# R7FS3A17 register map
Vendor: Renesas; Series: S3; File version: 1.2
CPU: CM4 r0p1, little endian, MPU, FPU, VTOR, 4 interrupt priority bits
Registers are 8-bit, read-write, reset 0x0 unless marked. A register's access mark holds for its fields unless they carry their own. Offsets are from the block's base; [hi:lo] are bit positions; <NAME> marks a mode.

## SDHI0 — SD Host Interface 0
Base 0x40062000
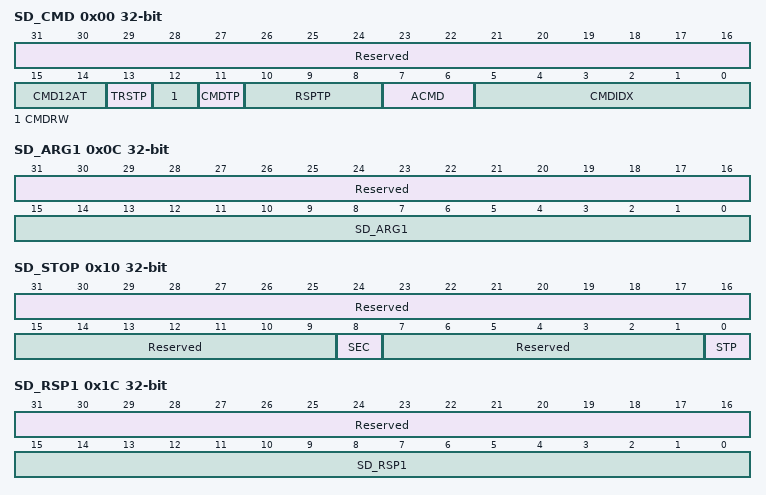
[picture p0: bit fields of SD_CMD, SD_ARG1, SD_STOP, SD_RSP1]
0x00 SD_CMD 32-bit — Command Type Register
  [31:16] Reserved — These bits are read as 0000000000000000. The write value should be 0000000000000000.
  [15:14] CMD12AT — CMD12 Automatic Issue Select
    0=CMD12 is automatically issued at multi-block transfer; 1=CMD12 is not automatically issued at multi-block transfer; other=others (Setting prohibited)
  [13] TRSTP — Block Transfer Select
    0=Single block transfer; 1=Multiple blocks transfer
  [12] CMDRW — Data Transfer Direction Select
    0=Write (SD/MMC host interface -> SD card/MMC); 1=Read (SD/MMC host interface <- SD card/MMC)
  [11] CMDTP — Data Transfer Select
    0=Command does not include data transfer (bc, bcr, or ac); 1=Command includes data transfer (adtc)
  [10:8] RSPTP — Response Type Select NOTE:Some commands cannot be used in Normal Mode. Refer to Table 37.3 and set the RSPTP[2:0] bits.
    0=Normal mode The response type and the transfer mode are selected by SD_CMD[7:0], and the SD_CMD[15:11] setting is disabled; 3=Expansion mode and no response; 4=Expansion mode and R1, R5, R6, or R7 response; 5=Expansion mode and R1b response; 6=Expansion mode and R2 response; 7=Expansion mode and R3 or R4 response; other=others (Settings prohibited.)
  [7:6] ACMD — Command Type Select
    0=CMD; 1=ACMD; other=others (Setting prohibited)
  [5:0] CMDIDX — Command Index Field Value Select These bits specify Command Format[45:40] (command index). [Examples] CMD6: SD_CMD[7:0] = 8'b00_000110 CMD18: SD_CMD[7:0] = 8'b00_010010 ACMD13: SD_CMD[7:0] = 8'b01_001101
0x08 SD_ARG 32-bit — SD Command Argument Register
  [31:0] SD_ARG — Argument Register Set command format[39:8] (argument)
0x0C SD_ARG1 32-bit — SD Command Argument Register 1
  [31:16] Reserved — These bits are read as 0000000000000000. The write value should be 0000000000000000.
  [15:0] SD_ARG1 — Argument Register 1 Set command format[39:24] (argument)
0x10 SD_STOP 32-bit — Data Stop Register
  [31:16] Reserved — These bits are read as 0000000000000000. The write value should be 0000000000000000.
  [15:9] Reserved — These bits are read as 0000000. The write value should be 0000000.
  [8] SEC — Block Count Register Value Select Set SEC to 1 at multiple block transfer. When SD_CMD is set as follows to start the command sequence while SEC is set to 1, CMD12 is automatically issued to stop multi-block transfer with the number of blocks which is set to SD_SECCNT. 1. CMD18 or CMD25 in normal mode (SD_CMD[10:8] = 000) 2. SD_CMD[15:13] = 001 in extended mode (CMD12 is automatically issued, multiple block transfer) When the command sequence is halted because of a communications error or timeout, CMD12 is not automatically issued. NOTE: Do not change the value of this bit when the CBSY bit in SD_INFO2 is set to 1.
    0=SD_SECCNT register value is invalid; 1=SD_SECCNT register value is valid
  [7:1] Reserved — These bits are read as 0000000. The write value should be 0000000.
  [0] STP — Transfer Stop Data transfer stops when this bit is set to 1
0x14 SD_SECCNT 32-bit — Block Count Register
  [31:0] SD_SECCNT — Number of Transfer Blocks NOTE: Do not change the value of this bit when the CBSY bit in SD_INFO2 is set to 1.
0x18 SD_RSP10 32-bit ro — SD Card Response Register 10
  [31:0] SD_RSP10 — Store the response from the SD card/MMC
0x1C SD_RSP1 32-bit ro — SD Card Response Register 1
  [31:16] Reserved — These bits are read as 0000000000000000.
  [15:0] SD_RSP1 — Store the response from the SD card/MMC
0x20 SD_RSP32 32-bit ro — SD Card Response Register 32
  [31:0] SD_RSP32 — Store the response from the SD card/MMC
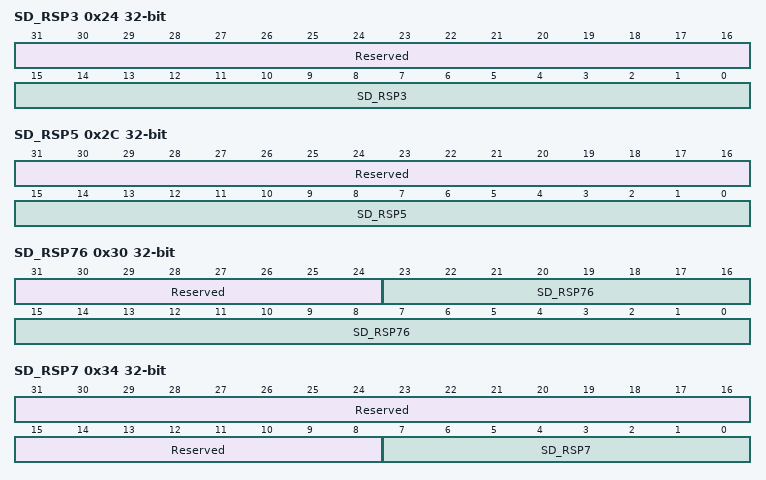
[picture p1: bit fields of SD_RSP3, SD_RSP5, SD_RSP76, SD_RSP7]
0x24 SD_RSP3 32-bit ro — SD Card Response Register 3
  [31:16] Reserved — These bits are read as 0000000000000000.
  [15:0] SD_RSP3 — Store the response from the SD card/MMC
0x28 SD_RSP54 32-bit ro — SD Card Response Register 54
  [31:0] SD_RSP54 — Store the response from the SD card/MMC
0x2C SD_RSP5 32-bit ro — SD Card Response Register 5
  [31:16] Reserved — These bits are read as 0000000000000000.
  [15:0] SD_RSP5 — Store the response from the SD card/MMC
0x30 SD_RSP76 32-bit ro — SD Card Response Register 76
  [31:24] Reserved — These bits are read as 00000000.
  [23:0] SD_RSP76 — Store the response from the SD card/MMC
0x34 SD_RSP7 32-bit ro — SD Card Response Register 7
  [31:8] Reserved — These bits are read as 000000000000000000000000.
  [7:0] SD_RSP7 — Store the response from the SD card/MMC
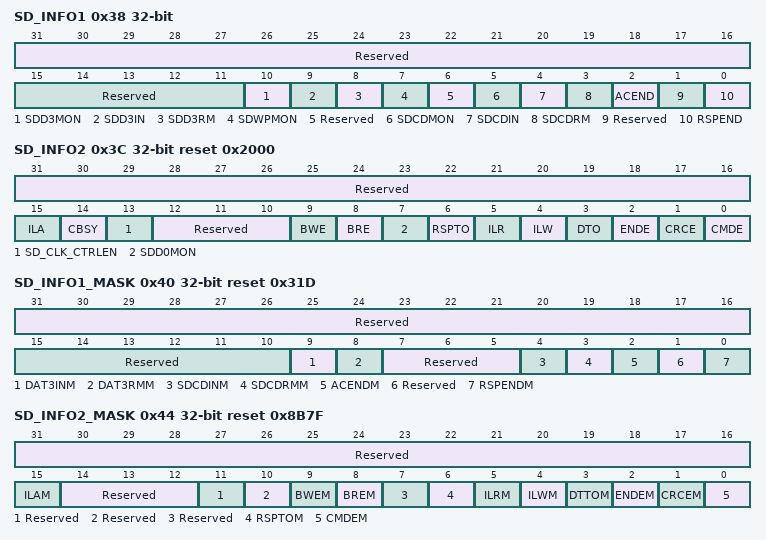
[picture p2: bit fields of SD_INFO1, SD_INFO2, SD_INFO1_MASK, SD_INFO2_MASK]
0x38 SD_INFO1 32-bit (reset mask 0xFFFFFB5F) — SD Card Interrupt Flag Register 1
  [31:16] Reserved — These bits are read as 0000000000000000. The write value should be 0000000000000000.
  [15:11] Reserved — These bits are read as 00000. The write value should be 00000.
  [10] SDD3MON ro — Inticates the SDnDAT3 State Flag
    0=SDnDAT3 is set to 0; 1=SDnDAT3 is set to 1
  [9] SDD3IN write-0-clears read-modifies — SDnDAT3 Card Insertion Flag
    0=SD card insertion is not detected; 1=SD card insertion is detected
  [8] SDD3RM write-0-clears read-modifies — SD0DAT3 Card Removal Flag
    0=SD card removal is not detected; 1=SD card removal is detected
  [7] SDWPMON ro — SD0WP Pin Monitor Detection Flag
    0=SDnWP is set to 1; 1=SDnWP is set to 0
  [6] Reserved — This bit is read as 0. The write value should be 0.
  [5] SDCDMON ro — SD0CD Pin Monitor Detection Flag
    0=SD0WP pin level is high; 1=SD0WP pin level is low
  [4] SDCDIN write-0-clears read-modifies — SD0CD Insertion Detection Flag
    0=SD card/MMC insertion is not detected by the SD0CD pin; 1=SD card/MMC insertion is detected by the SD0CD pin
  [3] SDCDRM write-0-clears read-modifies — SD0CD Removal Detection Flag
    0=SD card/MMC removal is not detected by the SD0CD pin; 1=SD card/MMC removal is detected by the SD0CD pin
  [2] ACEND write-0-clears read-modifies — Access End Detection Flag
    0=Access end is not detected; 1=Access end is detected
  [1] Reserved — This bit is read as 0. The write value should be 0.
  [0] RSPEND — Response End Detection Flag
    0=Response end is not detected; 1=Response end is detected
0x3C SD_INFO2 32-bit reset 0x2000 (reset mask 0xFFFFFF7F) — SD Card Interrupt Flag Register 2
  [31:16] Reserved — These bits are read as 0000000000000000. The write value should be 0000000000000000.
  [15] ILA write-0-clears read-modifies — Illegal Access Error
    0=Illegal access error is not detected; 1=Illegal access error is detected
  [14] CBSY ro — Command Type Register Busy
    0=A command sequence is being executed; 1=A command sequence has been completed
  [13] SD_CLK_CTRLEN ro — When a command sequence is started by writing to SD_CMD, the CBSY bit is set to 1 and, at the same time, the SCLKDIVEN bit is set to 0. The SCLKDIVEN bit is set to 1 after 8 cycles of SDCLK have elapsed after setting of the CBSY bit to 0 due to completion of the command sequence.
    0=The SD/MMC bus (CMD, DAT) is busy. Writing to the SCLKEN and DIV bits in SD_CLK_CTRL is not possible.; 1=The SD/MMC bus (CMD, DAT) is not busy
  [12:10] Reserved — These bits are read as 000. The write value should be 000.
  [9] BWE write-0-clears read-modifies — SD_BUF Write Enable
    1=Data can be written in SD_BUF0; 0=Data cannot be written in SD_BUF0
  [8] BRE write-0-clears read-modifies — SD_BUF Read Enable
    1=Data can be read from SD_BUF0; 0=Data cannot be read from SD_BUF0
  [7] SDD0MON ro — SDDAT0 Indicates the SDDAT0 state of the port specified by SD_PORTSEL.
    1=SDDAT0 is set to 1; 0=SDDAT0 is set to 0
  [6] RSPTO write-0-clears read-modifies — Response Timeout
    0=Response timeout is not detected; 1=Response timeout is detected
  [5] ILR write-0-clears read-modifies — SD_BUF Illegal Read Access
    0=Illegal read access to the SD_BUF register is not detected; 1=Illegal read access to the SD_BUF register is detected
  [4] ILW write-0-clears read-modifies — SD_BUF Illegal Write Access
    0=Illegal write access to the SD_BUF register is not detected; 1=Illegal write access to the SD_BUF register is detected
  [3] DTO write-0-clears read-modifies — Data Timeout
    0=Data timeout not is detected; 1=Data timeout is detected
  [2] ENDE write-0-clears read-modifies — END Error
    0=End bit error is not detected; 1=End bit error is detected
  [1] CRCE write-0-clears read-modifies — CRC Error
    0=CRC error is not detected; 1=CRC error is detected
  [0] CMDE write-0-clears read-modifies — Command Error
    0=Command error is not detected; 1=Command error is detected
0x40 SD_INFO1_MASK 32-bit reset 0x31D — SD_INFO1 Interrupt Mask Register
  [31:16] Reserved — These bits are read as 0000000000000000. The write value should be 0000000000000000.
  [15:10] Reserved — These bits are read as 000000. The write value should be 000000.
  [9] DAT3INM — SDnDAT3 Card Insertion Interrupt Request Mask
    0=SD card insertion interrupt request by the SDnDAT3 is not masked; 1=SD card insertion interrupt request by the SDnDAT3 is masked
  [8] DAT3RMM — SDnDAT3 Card Removal Interrupt Request Mask
    0=SD card removal interrupt request by the SDnDAT3 is not masked; 1=SD card removal interrupt request by the SDnDAT3 is masked
  [7:5] Reserved — These bits are read as 000. The write value should be 000.
  [4] SDCDINM — SD0CD Insertion Interrupt Request Mask
    0=SD card/MMC insertion interrupt request by the SD0CD pin is not masked; 1=SD card/MMC insertion interrupt request by the SD0CD pin is masked
  [3] SDCDRMM — SD0CD Removal Interrupt Request Mask
    0=SD card/MMC removal interrupt request by the SD0CD pin is not masked; 1=SD card/MMC removal interrupt request by the SD0CD pin is masked
  [2] ACENDM — Access End Interrupt Request Mask
    0=Access end interrupt request is not masked; 1=Access end interrupt request is masked
  [1] Reserved — This bit is read as 0. The write value should be 0.
  [0] RSPENDM — Response End Interrupt Request Mask
    0=Response end interrupt request is not masked; 1=Response end interrupt request is masked
0x44 SD_INFO2_MASK 32-bit reset 0x8B7F — SD_INFO2 Interrupt Mask Register
  [31:16] Reserved — These bits are read as 0000000000000000. The write value should be 0000000000000000.
  [15] ILAM — Illegal Access Error Interrupt Request Mask
    0=Illegal access error interrupt request is not masked; 1=Illegal access error interrupt request is masked
  [14:12] Reserved — These bits are read as 000. The write value should be 000.
  [11] Reserved — This bit is read as 1. The write value should be 1.
  [10] Reserved — This bit is read as 0. The write value should be 0.
  [9] BWEM — BWE Interrupt Request Mask
    0=Write enable interrupt request for the SD_BUF register is not masked; 1=Write enable interrupt request for the SD_BUF register is masked
  [8] BREM — BRE Interrupt Request Mask
    0=Read enable interrupt request for the SD buffer not masked; 1=Read enable interrupt request for the SD buffer masked
  [7] Reserved — This bit is read as 0. The write value should be 0.
  [6] RSPTOM — Response Timeout Interrupt Request Mask
    0=Response timeout interrupt request is not masked; 1=Response timeout interrupt request is masked
  [5] ILRM — SD_BUF Register Illegal Read Interrupt Request Mask
    0=Illegal read detection interrupt request for the SD_BUF register is not masked; 1=Illegal read detection interrupt request for the SD_BUF register is masked
  [4] ILWM — SD_BUF Register Illegal Write Interrupt Request Mask
    0=Illegal write detection interrupt request for the SD_BUF register is not masked; 1=Illegal write detection interrupt request for the SD_BUF register is masked
  [3] DTTOM — Data Timeout Interrupt Request Mask
    0=Data timeout interrupt request is not masked; 1=Data timeout interrupt request is masked
  [2] ENDEM — End Bit Error Interrupt Request Mask
    0=End bit detection error interrupt request is not masked; 1=End bit detection error interrupt request is masked
  [1] CRCEM — CRC Error Interrupt Request Mask
    0=CRC error interrupt request is not masked; 1=CRC error interrupt request is masked
  [0] CMDEM — Command Error Interrupt Request Mask
    0=Command error interrupt request is not masked; 1=Command error interrupt request is masked
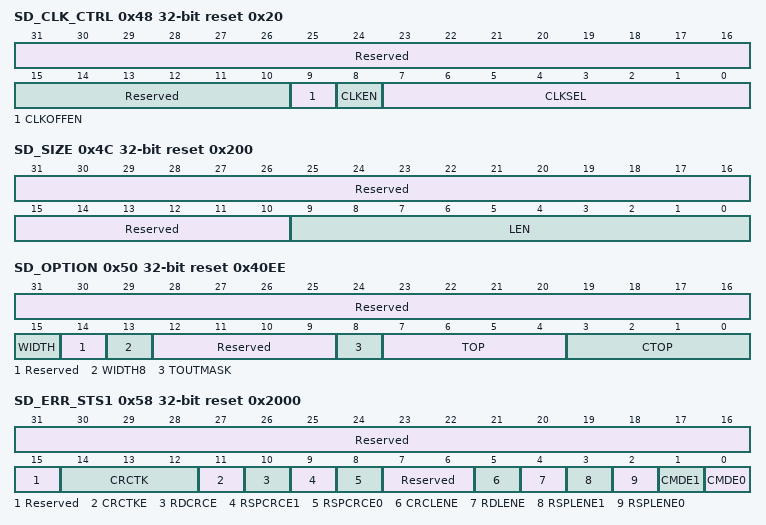
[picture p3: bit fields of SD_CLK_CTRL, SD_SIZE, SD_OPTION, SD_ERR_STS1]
0x48 SD_CLK_CTRL 32-bit reset 0x20 — SD Clock Control Register
  [31:16] Reserved — These bits are read as 0000000000000000. The write value should be 0000000000000000.
  [15:10] Reserved — These bits are read as 000000. The write value should be 000000.
  [9] CLKOFFEN — SD/MMC Clock Output Automatic Control Enable
    0=Automatic control for SD/MMC Clock output is disabled; 1=Automatic control for SD/MMC Clock output is enabled
  [8] CLKEN — SD/MMC Clock Output Control Enable
    0=SD/MMC Clock output is disabled. The SDCLK signal is fixed 0.; 1=SD/MMC Clock output is enabled
  [7:0] CLKSEL — SDHI Clock Frequency Select
    0=PCLKA divided by 2; 1=PCLKA divided by 4; 2=PCLKA divided by 8; 4=PCLKA divided by 16; 8=PCLKA divided by 32; 16=PCLKA divided by 64; 32=PCLKA divided by 128; 64=PCLKA divided by 256; 128=PCLKA divided by 512; other=others (Settings prohibited.)
0x4C SD_SIZE 32-bit reset 0x200 — Transfer Data Length Register
  [31:10] Reserved — These bits are read as 0000000000000000000000. The write value should be 0000000000000000000000.
  [9:0] LEN — Transfer Data Size These bits specify a size between 1 and 512 bytes for the transfer of single blocks. In cases of multiple block transfer with automatic issuing of CMD12 (CMD18 and CMD25), the only specifiable transfer data size is 512 bytes. Furthermore, in cases of multiple block transfer without automatic issuing of CMD12, as well as 512 bytes, 32, 64, 128, and 256 bytes are specifiable. However, in the reading of 32, 64, 128, and 256 bytes for the transfer of multiple blocks, this is restricted to multiple block transfer by CMD53.Additionally, if a command accompanies data transfer, do not set these bits to 0.
0x50 SD_OPTION 32-bit reset 0x40EE — SD Card Access Control Option Register
  [31:16] Reserved — These bits are read as 0000000000000000. The write value should be 0000000000000000.
  [15] WIDTH — Bus Width NOTE: The initial value is applied at a reset and when the SOFT_RST.SDRST flag is 0.
    0=4-bit width (WIDTH8=0) / 8-bit width (WIDTH8=1); 1=1-bit width (WIDTH8=0 or 1 )
  [14] Reserved — This bit is read as 1. The write value should be 1.
  [13] WIDTH8 — Bus Width see b15, WIDTH bit
  [12:9] Reserved — These bits are read as 0000. The write value should be 0000.
  [8] TOUTMASK — Timeout MASK When timeout occurs in case of inactivating timeout, software reset should be executed to terminate command sequence.
    0=Activate Timeout; 1=Inactivate Timeout(RSPTO bit and DTO bit of SD_INFO2 and SD_ERR_STS2 won't be set)
  [7:4] TOP — Timeout Counter
    15=Setting prohibited; other=others (SDHI clock x 2^(TOP+13))
  [3:0] CTOP — Card Detection Time Counter
    15=Setting prohibited; other=others (PCLKA x 2^(TOP+10))
0x58 SD_ERR_STS1 32-bit ro reset 0x2000 — SD Error Status Register 1
  [31:15] Reserved — These bits are read as 00000000000000000.
  [14:12] CRCTK — CRC Status Token Store the CRC status token value (normal value is 010b)
  [11] CRCTKE — CRC Status Token Error Flag
    0=Error detected in CRC status token; 1=No error detected in CRC status token
  [10] RDCRCE — Read Data CRC Error Flag
    0=CRC error detected in read data; 1=No CRC error detected in read data
  [9] RSPCRCE1 — Response CRC Error Flag 1 NOTE: In cases where CMD12 is issued by setting a command index in SD_CMD, this is indicated in RSPCRCE0.
    0=CRC error detected in command response; 1=No CRC error detected in command response (by setting the SD_CMD.CMDIDX[5:0] bits, the error that occurs by issuing CMD12 is indicated by the RSPCRCE0 flag)
  [8] RSPCRCE0 — Response CRC Error Flag 0 NOTE: other than a response to a command issued within a command sequence
    0=CRC error detected in command response; 1=No CRC error detected in command response
  [7:6] Reserved — These bits are read as 00.
  [5] CRCLENE — CRC Status Token Length Error Flag
    0=CRC status token length error did not occur; 1=CRC status token length error occurred
  [4] RDLENE — Read Data Length Error Flag
    0=Read data length error did not occur; 1=Read data length error occurred
  [3] RSPLENE1 — Response Length Error Flag 1 NOTE: In cases where CMD12 is issued by setting a command index in SD_CMD, this is indicated in RSPLENE0.
    0=Command response length is error free; 1=Command response length is in error (by setting the SD_CMD.CMDIDX[5:0] bits, the error that occurs by issuing CMD12 is indicated by the RSPLENE0 flag)
  [2] RSPLENE0 — Response Length Error Flag 0 NOTE: other than a response to a command issued within a command sequence
    0=Command1 response length is error free; 1=Command1 response length is in error
  [1] CMDE1 — Command Error Flag 1 NOTE: In cases where CMD12 is issued by setting a command index in SD_CMD, this is Indicated in CMDE0.
    0=After a command*2 was issued, a response was received in less than 640 cycles of the SD/MMC clock; 1=After a command*2 was issued, a response was not received even after 640 cycles or more of the SD/MMC clock elapsed (by setting the SD_CMD.CMDIDX[5:0] bits, the error that occurs by issuing CMD12 is indicated by the RSPTO0 flag)
  [0] CMDE0 — Command Error Flag 0 NOTE: other than a response to a command issued within a command sequence
    0=After a command*1 was issued, a response was received in less than 640 cycles of the SD/MMC clock; 1=After a command*1 was issued, a response was not received even after 640 cycles or more of the SD/MMC clock elapsed
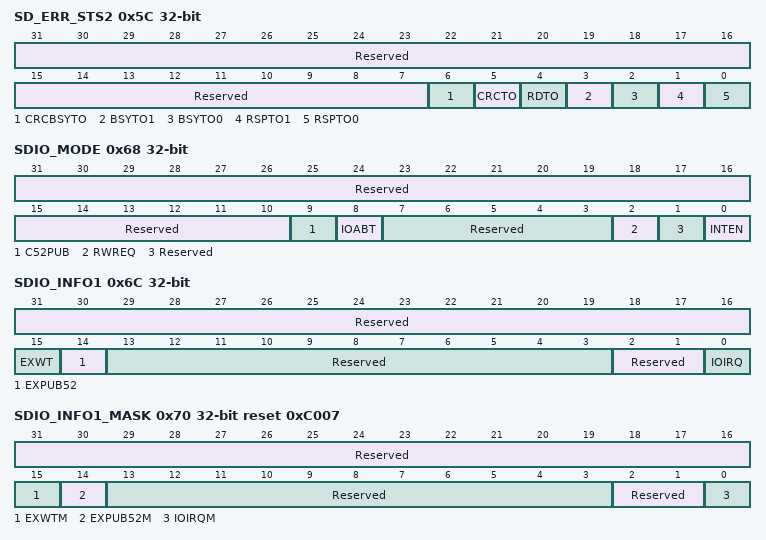
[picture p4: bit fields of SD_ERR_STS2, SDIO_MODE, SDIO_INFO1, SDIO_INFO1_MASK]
0x5C SD_ERR_STS2 32-bit ro — SD Error Status Register 2
  [31:7] Reserved — These bits are read as 0000000000000000000000000.
  [6] CRCBSYTO — CRC Status Token Busy Timeout Flag
    0=After a CRC status token was received, the SD/MMC was released from the busy state during the specified period; 1=After a CRC status token was received, the SD/MMC is in the busy state even after the specified period elapsed
  [5] CRCTO — CRC Status Token Timeout Flag
    0=After CMD12 was automatically issued, the SD/MMC was released from the busy state during the specified period; 1=After CMD12 was automatically issued, the SD/MMC was in the busy state even after the specified period*3 elapsed (by setting the SD_CMD.CMDIDX[5:0] bits, the error that occurs by issuing CMD12 is indicated by the BSYTO0 flag)
  [4] RDTO — Read Data Timeout Flag
    0=Not timeout; 1=The read data is not received though a longer time than N-cycle has elapsed after read command. / The read data for the next block are not received though a longer time than N-cycle has elapsed after the reception of read data. / The read data for the next block are not received though a longer time than N-cycle has elapsed after release of the read wait state.
  [3] BSYTO1 — Busy Timeout Flag 1
    0=After CMD12 was automatically issued, the SD/MMC was released from the busy state during the specified period; 1=After CMD12 was automatically issued, the SD/MMC was in the busy state even after the specified period elapsed (by setting the SD_CMD.CMDIDX[5:0] bits, the error that occurs by issuing CMD12 is indicated by the BSYTO0 flag)
  [2] BSYTO0 — Busy Timeout Flag 0
    0=After the R1b response was received, the SD/MMC was released from the busy state during the specified period; 1=After the R1b response was received, the SD/MMC was in the busy state even after the specified period elapsed
  [1] RSPTO1 — Response Timeout Flag 1
    0=After a command was issued, a response was received in less than 640 cycles of the SD/MMC clock; 1=After a command was issued, a response was not received even after 640 cycles or more of the SD/MMC clock elapsed (by setting the SD_CMD.CMDIDX[5:0] bits, the error that occurs by issuing CMD12 is indicated by the RSPTO0 flag)
  [0] RSPTO0 — Response Timeout Flag 0
    0=After a command was issued, a response was received in less than 640 cycles of the SD/MMC clock; 1=After a command was issued, a response was not received even after 640 cycles or more of the SD/MMC clock elapsed
0x60 SD_BUF0 32-bit reset not defined — SD Buffer Read/Write Register
  [31:0] SD_BUF — SD Buffer Register When writing to the SD card, the write data is written to this register. When reading from the SD card, the read data is read from this register. This register is internally connected to two 512-byte buffers. If both buffers are not empty when executing multiple block read, SD/MMC clock is stopped to suspend receiving data. When one of buffers is empty, SD/MMC clock is supplied to resume receiving data.
0x68 SDIO_MODE 32-bit — SDIO Mode Control Register
  [31:10] Reserved — These bits are read as 0000000000000000000000. The write value should be 0000000000000000000000.
  [9] C52PUB — SDIO None Abort
  [8] IOABT — SDIO Abort
  [7:3] Reserved — These bits are read as 00000. The write value should be 00000.
  [2] RWREQ — Read Wait Request
    0=SD/MMC exits read wait state; 1=Request for SD/MMC to enter read wait state
  [1] Reserved — This bit is read as 0. The write value should be 0.
  [0] INTEN — SDIO Interrupt Acceptance Enable
    0=SDIO interrupt accept disabled; 1=SDIO interrupt accept enabled
0x6C SDIO_INFO1 32-bit (reset mask 0xFFFFFFF9) — SDIO Interrupt Flag Register 1
  [31:16] Reserved — These bits are read as 0000000000000000. The write value should be 0000000000000000.
  [15] EXWT write-0-clears read-modifies — EXWT Status Flag NOTE: See manual
  [14] EXPUB52 write-0-clears read-modifies — EXPUB52 Status Flag NOTE: See manual
  [13:3] Reserved — These bits are read as 00000000000. The write value should be 00000000000.
  [2:1] Reserved — These bits are read as 00. The write value should be 00.
  [0] IOIRQ write-0-clears read-modifies — SDIO Interrupt Status
    0=SDIO interrupt not accepted; 1=SDIO interrupt accepted
0x70 SDIO_INFO1_MASK 32-bit reset 0xC007 — SDIO_INFO1 Interrupt Mask Register
  [31:16] Reserved — These bits are read as 0000000000000000. The write value should be 0000000000000000.
  [15] EXWTM — EXWT Interrupt Request Mask Control
    0=EXWT interrupt request is not masked; 1=EXWT interrupt request is masked
  [14] EXPUB52M — EXPUB52 Interrupt Request Mask Control
    0=EXPUB52 interrupt request is not masked; 1=EXPUB52 interrupt request is masked
  [13:3] Reserved — These bits are read as 00000000000. The write value should be 00000000000.
  [2:1] Reserved — These bits are read as 11. The write value should be 11.
  [0] IOIRQM — IOIRQ Interrupt Mask Control
    0=IOIRQ interrupt is not masked; 1=IOIRQ interrupt is masked
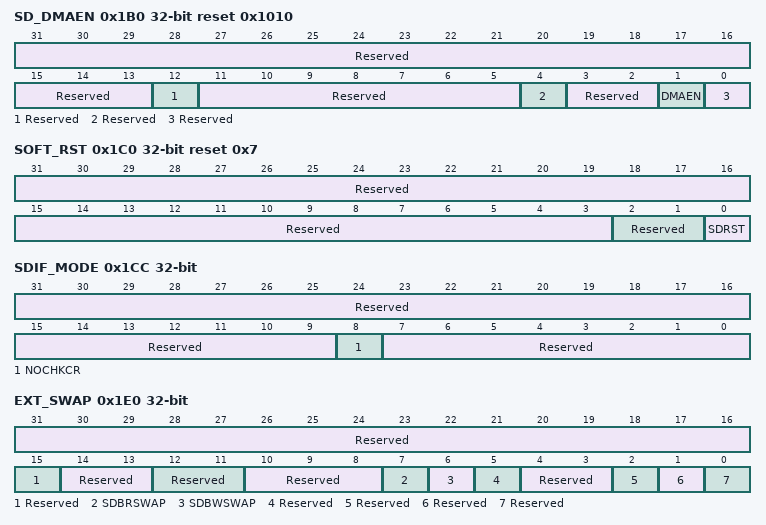
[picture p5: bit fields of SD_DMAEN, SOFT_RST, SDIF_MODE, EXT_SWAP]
0x1B0 SD_DMAEN 32-bit reset 0x1010 — DMA Mode Enable Register
  [31:13] Reserved — These bits are read as 0000000000000000000. The write value should be 0000000000000000000.
  [12] Reserved — This bit is read as 1. The write value should be 1.
  [11:5] Reserved — These bits are read as 0000000. The write value should be 0000000.
  [4] Reserved — This bit is read as 1. The write value should be 1.
  [3:2] Reserved — These bits are read as 00. The write value should be 00.
  [1] DMAEN — SD_BUF Read/Write DMA Transfer
    0=The SD_BUF read/write DMA transfer is disabled; 1=The SD_BUF read/write DMA transfer is enabled
  [0] Reserved — This bit is read as 0. The write value should be 0.
0x1C0 SOFT_RST 32-bit reset 0x7 — Software Reset Register
  [31:3] Reserved — These bits are read as 00000000000000000000000000000. The write value should be 00000000000000000000000000000.
  [2:1] Reserved — These bits are read as 11. The write value should be 11.
  [0] SDRST — Software Reset of SD I/F Unit
    0=Reset; 1=Reset released
0x1CC SDIF_MODE 32-bit — SD Interface Mode Setting Register
  [31:9] Reserved — These bits are read as 00000000000000000000000. The write value should be 00000000000000000000000.
  [8] NOCHKCR — CRC Check Mask (for MMC test commands)
    0=CRC check is valid; 1=CRC check is invalid(CRC16 value is ignored when read and CRC Status value is ignored when write)
  [7:0] Reserved — These bits are read as 00000000. The write value should be 00000000.
0x1E0 EXT_SWAP 32-bit — Swap Control Register
  [31:16] Reserved — These bits are read as 0000000000000000. The write value should be 0000000000000000.
  [15] Reserved — This bit is read as 0. The write value should be 0.
  [14:13] Reserved — These bits are read as 00. The write value should be 00.
  [12:11] Reserved — These bits are read as 00. The write value should be 00.
  [10:8] Reserved — These bits are read as 000. The write value should be 000.
  [7] SDBRSWAP — SD_BUF0 Swap Read
    0=The current data are read without swapping; 1=Swapping of the positions of the higher- and lower-order bytes of data for reading proceeds
  [6] SDBWSWAP — SD_BUF0 Swap Write
    0=The current data are written without swapping; 1=Swapping of the positions of the higher- and lower-order bytes of data for writing proceeds
  [5] Reserved — This bit is read as 0. The write value should be 0.
  [4:3] Reserved — These bits are read as 00. The write value should be 00.
  [2] Reserved — This bit is read as 0. The write value should be 0.
  [1] Reserved — This bit is read as 0. The write value should be 0.
  [0] Reserved — This bit is read as 0. The write value should be 0.
